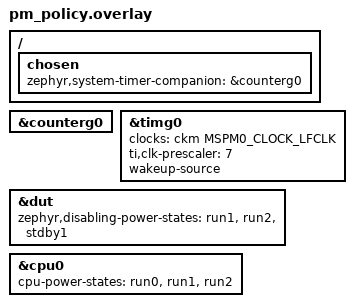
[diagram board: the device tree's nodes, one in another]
/*
 * SPDX-FileCopyrightText: Copyright (c) 2026 Texas Instruments
 * SPDX-License-Identifier: Apache-2.0
 */

/ {
	chosen {
		zephyr,system-timer-companion = &counterg0;
	};
};

&counterg0 {
	status = "okay";
};

&timg0 {
	status = "okay";
	clocks = <&ckm MSPM0_CLOCK_LFCLK>;
	ti,clk-prescaler = <7>;
	wakeup-source;
};

/* UART baud timing requires the RUN0/SLEEP0 ULPCLK frequency. */
&dut {
	zephyr,disabling-power-states = <&run1 &run2 &stdby1>;
};

/* STOP and STANDBY modes are not supported yet. */
&cpu0 {
	cpu-power-states = <&run0 &run1 &run2>;
};
